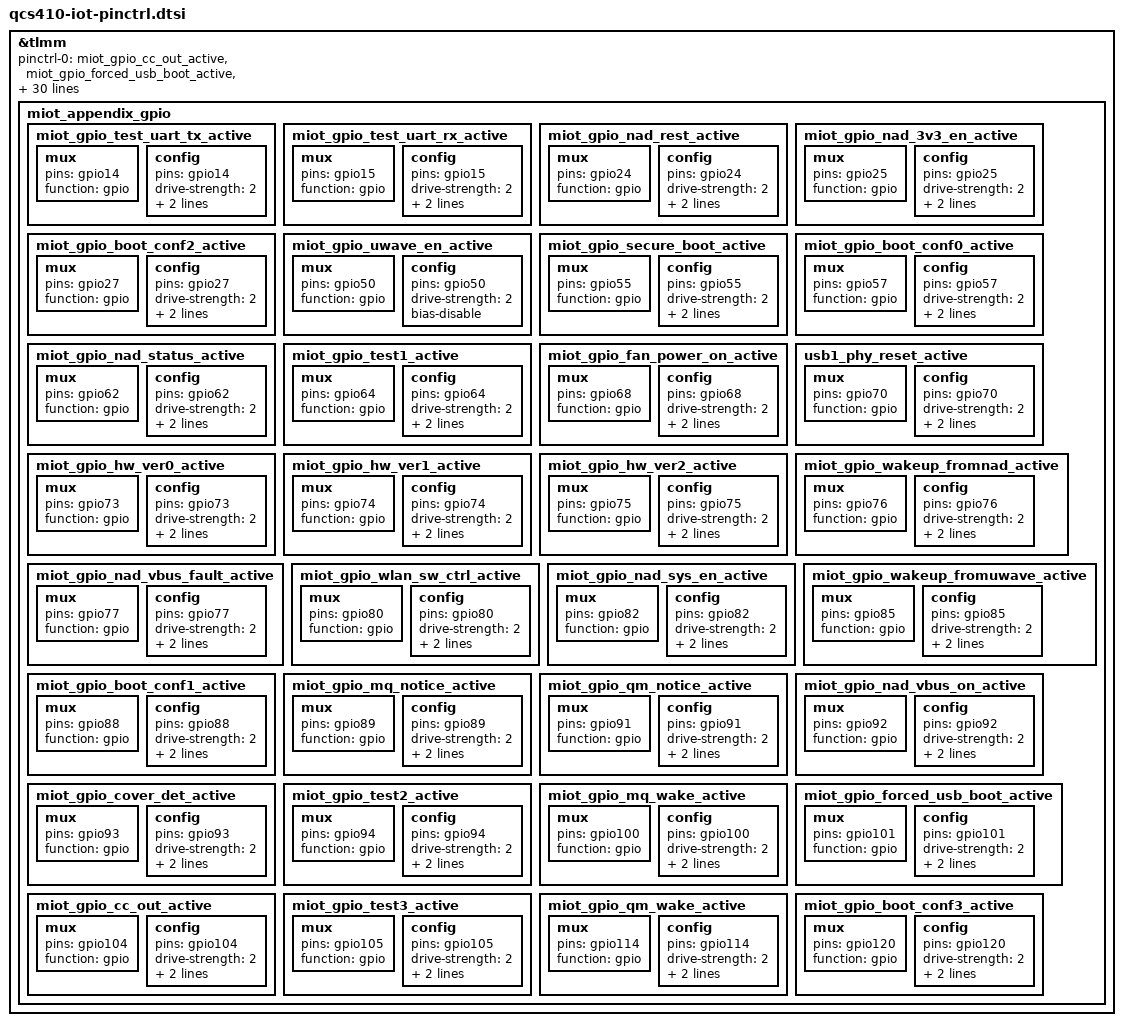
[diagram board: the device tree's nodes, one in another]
&tlmm {
	pinctrl-names = "default";
	pinctrl-0 = <&miot_gpio_cc_out_active
			 &miot_gpio_forced_usb_boot_active
			 &miot_gpio_boot_conf0_active
			 &miot_gpio_boot_conf1_active
			 &miot_gpio_boot_conf2_active
			 &miot_gpio_boot_conf3_active
			 &miot_gpio_secure_boot_active
			 &miot_gpio_mq_wake_active
			 &miot_gpio_mq_notice_active
			 &miot_gpio_qm_wake_active
			 &miot_gpio_qm_notice_active
			 &miot_gpio_test1_active
			 &miot_gpio_test2_active
			 &miot_gpio_test3_active
			 &miot_gpio_hw_ver0_active
			 &miot_gpio_hw_ver1_active
			 &miot_gpio_hw_ver2_active
			 &miot_gpio_wakeup_fromuwave_active
			 &miot_gpio_uwave_en_active
			 &miot_gpio_nad_rest_active
			 &miot_gpio_nad_sys_en_active
			 &miot_gpio_wakeup_fromnad_active
			 &miot_gpio_nad_status_active
			 &miot_gpio_wlan_sw_ctrl_active
			 &miot_gpio_test_uart_tx_active
			 &miot_gpio_test_uart_rx_active
			 &miot_gpio_nad_3v3_en_active
			 &miot_gpio_fan_power_on_active
			 &miot_gpio_nad_vbus_fault_active
			 &miot_gpio_nad_vbus_on_active
			 &miot_gpio_cover_det_active
			 &usb1_phy_reset_active>;

	miot_appendix_gpio {
		miot_gpio_test_uart_tx_active: miot_gpio_test_uart_tx_active {
			mux {
				pins = "gpio14";
				function = "gpio";
			};
			config {
				pins = "gpio14";
				drive-strength = <2>;
				output-low;
				bias-disable;
			};
		};
		miot_gpio_test_uart_rx_active: miot_gpio_test_uart_rx_active {
			mux {
				pins = "gpio15";
				function = "gpio";
			};
			config {
				pins = "gpio15";
				drive-strength = <2>;
				output-low;
				bias-disable;
			};
		};
		miot_gpio_nad_rest_active: miot_gpio_nad_rest_active {
			mux {
				pins = "gpio24";
				function = "gpio";
			};
			config {
				pins = "gpio24";
				drive-strength = <2>;
				output-low;
				bias-disable;
			};
		};
		miot_gpio_nad_3v3_en_active: miot_gpio_nad_3v3_en_active {
			mux {
				pins = "gpio25";
				function = "gpio";
			};
			config {
				pins = "gpio25";
				drive-strength = <2>;
				output-low;
				bias-disable;
			};
		};
		miot_gpio_boot_conf2_active: miot_gpio_boot_conf2_active {
			mux {
				pins = "gpio27";
				function = "gpio";
			};
			config {
				pins = "gpio27";
				drive-strength = <2>;
				input-enable;
				bias-disable;
			};
		};
		miot_gpio_uwave_en_active: miot_gpio_uwave_en_active {
			mux {
				pins = "gpio50";
				function = "gpio";
			};
			config {
				pins = "gpio50";
				drive-strength = <2>;
				bias-disable;
			};
		};
		miot_gpio_secure_boot_active: miot_gpio_secure_boot_active {
			mux {
				pins = "gpio55";
				function = "gpio";
			};
			config {
				pins = "gpio55";
				drive-strength = <2>;
				input-enable;
				bias-disable;
			};
		};
		miot_gpio_boot_conf0_active: miot_gpio_boot_conf0_active {
			mux {
				pins = "gpio57";
				function = "gpio";
			};
			config {
				pins = "gpio57";
				drive-strength = <2>;
				input-enable;
				bias-disable;
			};
		};
		miot_gpio_nad_status_active: miot_gpio_nad_status_active {
			mux {
				pins = "gpio62";
				function = "gpio";
			};
			config {
				pins = "gpio62";
				drive-strength = <2>;
				input-enable;
				bias-disable;
			};
		};
		miot_gpio_test1_active: miot_gpio_test1_active {
			mux {
				pins = "gpio64";
				function = "gpio";
			};
			config {
				pins = "gpio64";
				drive-strength = <2>;
				output-low;
				bias-disable;
			};
		};
		miot_gpio_fan_power_on_active: miot_gpio_fan_power_on_active {
			mux {
				pins = "gpio68";
				function = "gpio";
			};
			config {
				pins = "gpio68";
				drive-strength = <2>;
				output-low;
				bias-disable;
			};
		};
		usb1_phy_reset_active: usb1_phy_reset_active {
			mux {
				pins = "gpio70";
				function = "gpio";
			};
			config {
				pins = "gpio70";
				drive-strength = <2>;
				bias-disable;
				output-low;
			};
		};
		miot_gpio_hw_ver0_active: miot_gpio_hw_ver0_active {
			mux {
				pins = "gpio73";
				function = "gpio";
			};
			config {
				pins = "gpio73";
				drive-strength = <2>;
				input-enable;
				bias-disable;
			};
		};
		miot_gpio_hw_ver1_active: miot_gpio_hw_ver1_active {
			mux {
				pins = "gpio74";
				function = "gpio";
			};
			config {
				pins = "gpio74";
				drive-strength = <2>;
				input-enable;
				bias-disable;
			};
		};
		miot_gpio_hw_ver2_active: miot_gpio_hw_ver2_active {
			mux {
				pins = "gpio75";
				function = "gpio";
			};
			config {
				pins = "gpio75";
				drive-strength = <2>;
				input-enable;
				bias-disable;
			};
		};
		miot_gpio_wakeup_fromnad_active: miot_gpio_wakeup_fromnad_active {
			mux {
				pins = "gpio76";
				function = "gpio";
			};
			config {
				pins = "gpio76";
				drive-strength = <2>;
				input-enable;
				bias-disable;
			};
		};
		miot_gpio_nad_vbus_fault_active: miot_gpio_nad_vbus_fault_active {
			mux {
				pins = "gpio77";
				function = "gpio";
			};
			config {
				pins = "gpio77";
				drive-strength = <2>;
				input-enable;
				bias-disable;
			};
		};
		miot_gpio_wlan_sw_ctrl_active: miot_gpio_wlan_sw_ctrl_active {
			mux {
				pins = "gpio80";
				function = "gpio";
			};
			config {
				pins = "gpio80";
				drive-strength = <2>;
				input-enable;
				bias-disable;
			};
		};
		miot_gpio_nad_sys_en_active: miot_gpio_nad_sys_en_active {
			mux {
				pins = "gpio82";
				function = "gpio";
			};
			config {
				pins = "gpio82";
				drive-strength = <2>;
				output-low;
				bias-disable;
			};
		};
		miot_gpio_wakeup_fromuwave_active: miot_gpio_wakeup_fromuwave_active {
			mux {
				pins = "gpio85";
				function = "gpio";
			};
			config {
				pins = "gpio85";
				drive-strength = <2>;
				input-enable;
				bias-disable;
			};
		};
		miot_gpio_boot_conf1_active: miot_gpio_boot_conf1_active {
			mux {
				pins = "gpio88";
				function = "gpio";
			};
			config {
				pins = "gpio88";
				drive-strength = <2>;
				input-enable;
				bias-disable;
			};
		};
		miot_gpio_mq_notice_active: miot_gpio_mq_notice_active {
			mux {
				pins = "gpio89";
				function = "gpio";
			};
			config {
				pins = "gpio89";
				drive-strength = <2>;
				input-enable;
				bias-disable;
			};
		};
		miot_gpio_qm_notice_active: miot_gpio_qm_notice_active {
			mux {
				pins = "gpio91";
				function = "gpio";
			};
			config {
				pins = "gpio91";
				drive-strength = <2>;
				output-low;
				bias-disable;
			};
		};
		miot_gpio_nad_vbus_on_active: miot_gpio_nad_vbus_on_active {
			mux {
				pins = "gpio92";
				function = "gpio";
			};
			config {
				pins = "gpio92";
				drive-strength = <2>;
				output-low;
				bias-disable;
			};
		};
		miot_gpio_cover_det_active: miot_gpio_cover_det_active {
			mux {
				pins = "gpio93";
				function = "gpio";
			};
			config {
				pins = "gpio93";
				drive-strength = <2>;
				input-enable;
				bias-disable;
			};
		};
		miot_gpio_test2_active: miot_gpio_test2_active {
			mux {
				pins = "gpio94";
				function = "gpio";
			};
			config {
				pins = "gpio94";
				drive-strength = <2>;
				output-high;
				bias-disable;
			};
		};
		miot_gpio_mq_wake_active: miot_gpio_mq_wake_active {
			mux {
				pins = "gpio100";
				function = "gpio";
			};
			config {
				pins = "gpio100";
				drive-strength = <2>;
				input-enable;
				bias-disable;
			};
		};
		miot_gpio_forced_usb_boot_active: miot_gpio_forced_usb_boot_active {
			mux {
				pins = "gpio101";
				function = "gpio";
			};
			config {
				pins = "gpio101";
				drive-strength = <2>;
				input-enable;
				bias-disable;
			};
		};
		miot_gpio_cc_out_active: miot_gpio_cc_out_active {
			mux {
				pins = "gpio104";
				function = "gpio";
			};
			config {
				pins = "gpio104";
				drive-strength = <2>;
				input-enable;
				bias-disable;
			};
		};
		miot_gpio_test3_active: miot_gpio_test3_active {
			mux {
				pins = "gpio105";
				function = "gpio";
			};
			config {
				pins = "gpio105";
				drive-strength = <2>;
				output-low;
				bias-disable;
			};
		};
		miot_gpio_qm_wake_active: miot_gpio_qm_wake_active {
			mux {
				pins = "gpio114";
				function = "gpio";
			};
			config {
				pins = "gpio114";
				drive-strength = <2>;
				output-low;
				bias-disable;
			};
		};
		miot_gpio_boot_conf3_active: miot_gpio_boot_conf3_active {
			mux {
				pins = "gpio120";
				function = "gpio";
			};
			config {
				pins = "gpio120";
				drive-strength = <2>;
				input-enable;
				bias-disable;
			};
		};
	};
};


